# PIC32MZ2025DAR169 device description
Architecture: MIPS; Family: PIC32MZDA; Series: PIC32MZ
Registers are 32-bit, read-write, no defined reset value unless marked. A register's access mark holds for its fields unless they carry their own. Offsets are from the block's base; [hi:lo] are bit positions; {n}, {i} and the like mark numbered series; 'fields as' and 'values as' point back to an identical list.

## GPIO
Instances: GPIO 0x1f860000 in periph_pb4_std
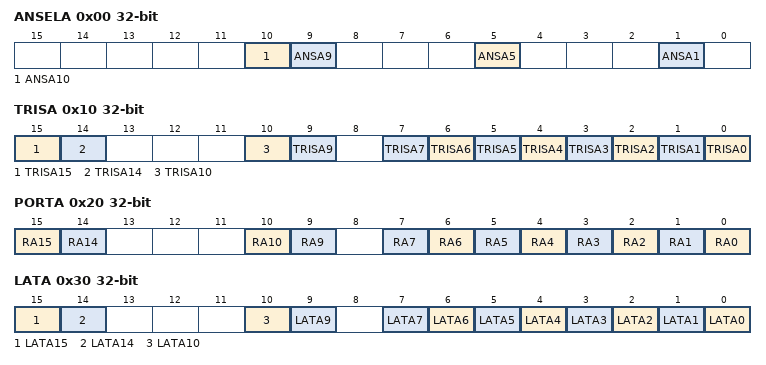
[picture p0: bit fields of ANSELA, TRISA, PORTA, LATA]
0x00 ANSELA
  [10] ANSA10, [9] ANSA9, [5] ANSA5, [1] ANSA1
0x10 TRISA
  [15] TRISA15, [14] TRISA14, [10] TRISA10, [9] TRISA9, [n] TRISA{n} (n=0..7)
0x20 PORTA
  [15] RA15, [14] RA14, [10] RA10, [9] RA9, [n] RA{n} (n=0..7)
0x30 LATA
  [15] LATA15, [14] LATA14, [10] LATA10, [9] LATA9, [n] LATA{n} (n=0..7)
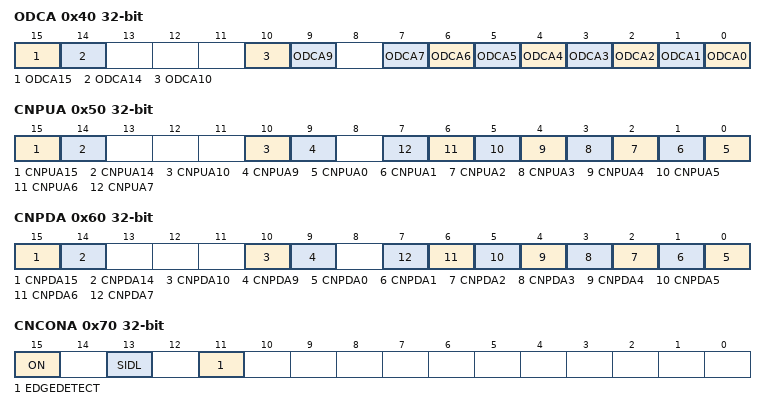
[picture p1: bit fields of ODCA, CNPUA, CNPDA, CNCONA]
0x40 ODCA
  [15] ODCA15, [14] ODCA14, [10] ODCA10, [9] ODCA9, [n] ODCA{n} (n=0..7)
0x50 CNPUA
  [15] CNPUA15, [14] CNPUA14, [10] CNPUA10, [9] CNPUA9, [n] CNPUA{n} (n=0..7)
0x60 CNPDA
  [15] CNPDA15, [14] CNPDA14, [10] CNPDA10, [9] CNPDA9, [n] CNPDA{n} (n=0..7)
0x70 CNCONA — Change Notice control for PORTx Register
  [15] ON — Change Notice Control ON bit
    1=CN is enabled; 0=CN is disabled
  [13] SIDL
  [11] EDGEDETECT — Change Notification Style bit
    1=Edge Style. Detect edge transitions (CNFx used for CN Event).; 0=Mismatch Style. Detect change from last PORTx read (CNSTATx used for CN Event).
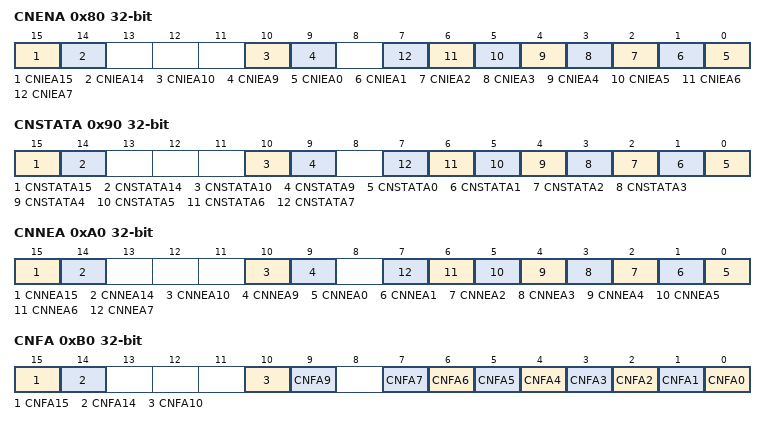
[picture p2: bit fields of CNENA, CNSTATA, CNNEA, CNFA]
0x80 CNENA
  [15] CNIEA15, [14] CNIEA14, [10] CNIEA10, [9] CNIEA9, [n] CNIEA{n} (n=0..7)
0x90 CNSTATA
  [15] CNSTATA15, [14] CNSTATA14, [10] CNSTATA10, [9] CNSTATA9, [n] CNSTATA{n} (n=0..7)
0xA0 CNNEA
  [15] CNNEA15, [14] CNNEA14, [10] CNNEA10, [9] CNNEA9, [n] CNNEA{n} (n=0..7)
0xB0 CNFA
  [15] CNFA15, [14] CNFA14, [10] CNFA10, [9] CNFA9, [n] CNFA{n} (n=0..7)
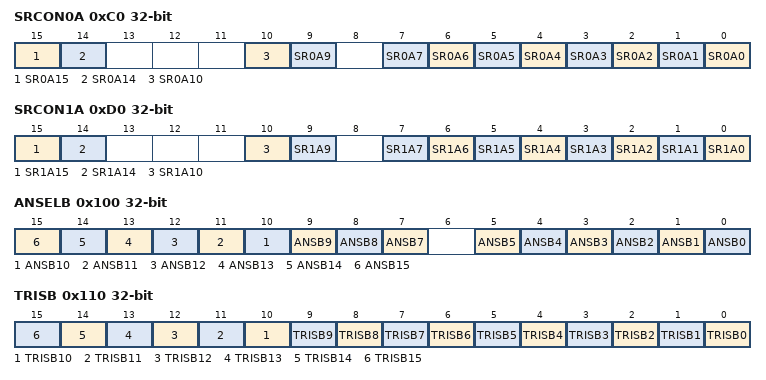
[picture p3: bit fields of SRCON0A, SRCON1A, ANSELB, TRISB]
0xC0 SRCON0A
  [15] SR0A15, [14] SR0A14, [10] SR0A10, [9] SR0A9, [n] SR0A{n} (n=0..7)
0xD0 SRCON1A
  [15] SR1A15, [14] SR1A14, [10] SR1A10, [9] SR1A9, [n] SR1A{n} (n=0..7)
0x100 ANSELB
  [n] ANSB{n} (n=7..15), [n] ANSB{n} (n=0..5)
0x110 TRISB
  [n] TRISB{n} (n=0..15)
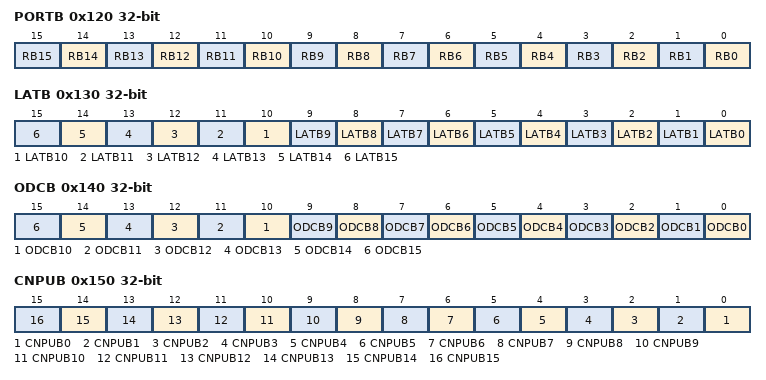
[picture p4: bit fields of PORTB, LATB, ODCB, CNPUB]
0x120 PORTB
  [n] RB{n} (n=0..15)
0x130 LATB
  [n] LATB{n} (n=0..15)
0x140 ODCB
  [n] ODCB{n} (n=0..15)
0x150 CNPUB
  [n] CNPUB{n} (n=0..15)
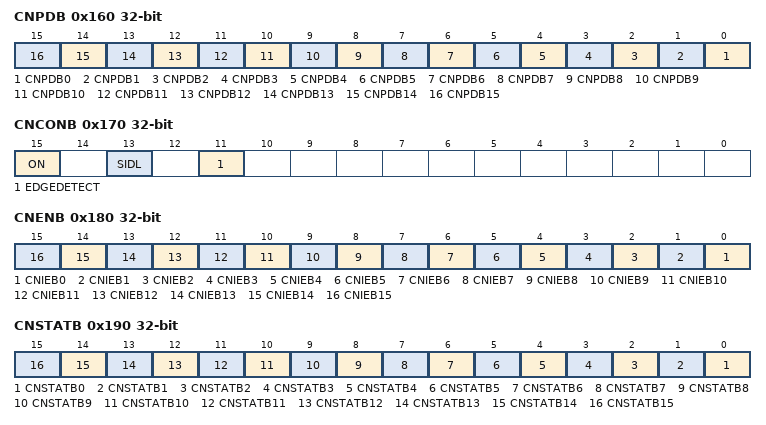
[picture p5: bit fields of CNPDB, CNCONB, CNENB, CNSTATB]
0x160 CNPDB
  [n] CNPDB{n} (n=0..15)
0x170 CNCONB — Change Notice control for PORTx Register
  fields as CNCONA
0x180 CNENB
  [n] CNIEB{n} (n=0..15)
0x190 CNSTATB
  [n] CNSTATB{n} (n=0..15)
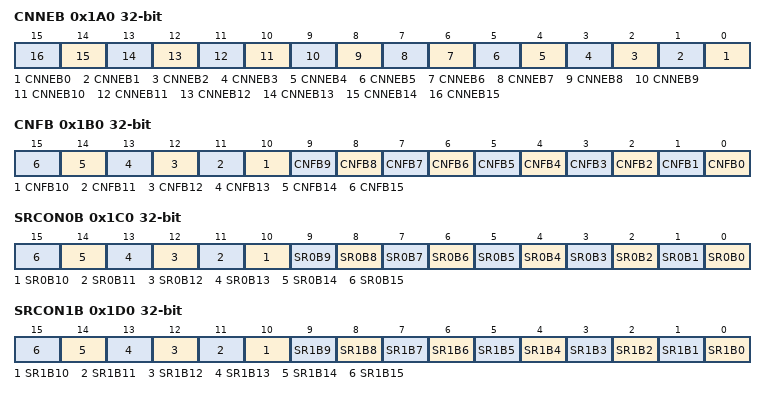
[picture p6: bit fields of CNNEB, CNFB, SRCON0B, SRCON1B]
0x1A0 CNNEB
  [n] CNNEB{n} (n=0..15)
0x1B0 CNFB
  [n] CNFB{n} (n=0..15)
0x1C0 SRCON0B
  [n] SR0B{n} (n=0..15)
0x1D0 SRCON1B
  [n] SR1B{n} (n=0..15)
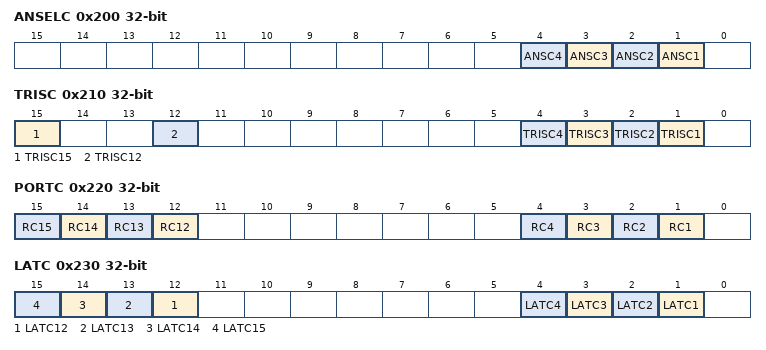
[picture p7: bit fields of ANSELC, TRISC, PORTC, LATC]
0x200 ANSELC
  [n] ANSC{n} (n=1..4)
0x210 TRISC
  [15] TRISC15, [12] TRISC12, [n] TRISC{n} (n=1..4)
0x220 PORTC
  [n] RC{n} (n=12..15), [n] RC{n} (n=1..4)
0x230 LATC
  [n] LATC{n} (n=12..15), [n] LATC{n} (n=1..4)
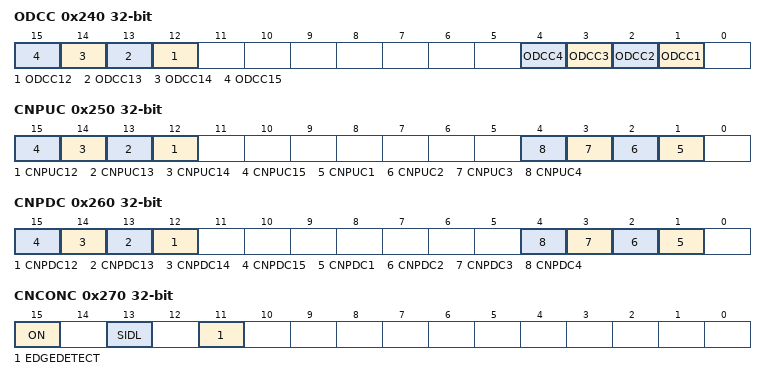
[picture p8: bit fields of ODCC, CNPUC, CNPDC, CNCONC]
0x240 ODCC
  [n] ODCC{n} (n=12..15), [n] ODCC{n} (n=1..4)
0x250 CNPUC
  [n] CNPUC{n} (n=12..15), [n] CNPUC{n} (n=1..4)
0x260 CNPDC
  [n] CNPDC{n} (n=12..15), [n] CNPDC{n} (n=1..4)
0x270 CNCONC — Change Notice control for PORTx Register
  fields as CNCONA
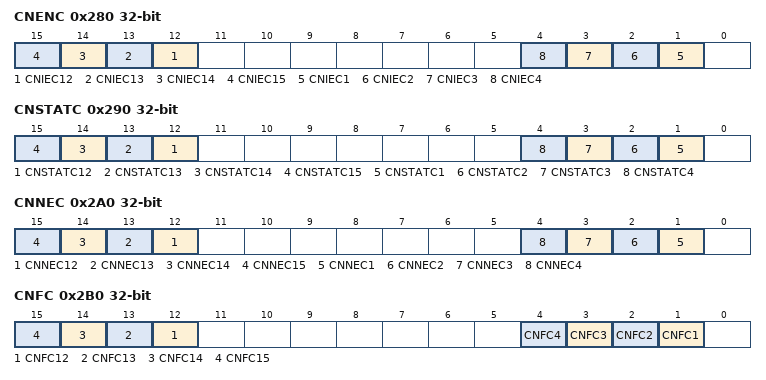
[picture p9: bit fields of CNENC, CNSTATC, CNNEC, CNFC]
0x280 CNENC
  [n] CNIEC{n} (n=12..15), [n] CNIEC{n} (n=1..4)
0x290 CNSTATC
  [n] CNSTATC{n} (n=12..15), [n] CNSTATC{n} (n=1..4)
0x2A0 CNNEC
  [n] CNNEC{n} (n=12..15), [n] CNNEC{n} (n=1..4)
0x2B0 CNFC
  [n] CNFC{n} (n=12..15), [n] CNFC{n} (n=1..4)
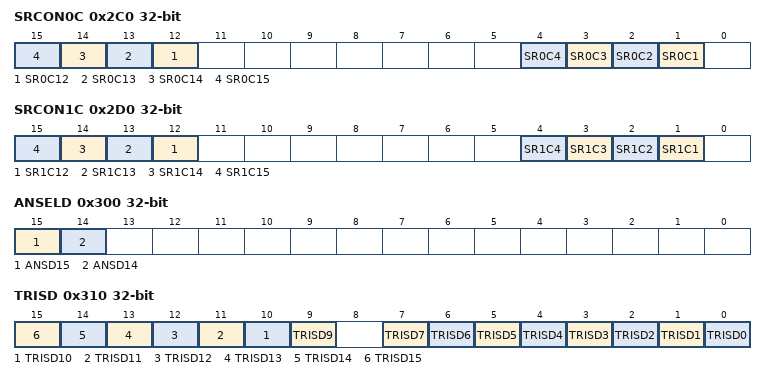
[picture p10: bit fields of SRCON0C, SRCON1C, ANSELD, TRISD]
0x2C0 SRCON0C
  [n] SR0C{n} (n=12..15), [n] SR0C{n} (n=1..4)
0x2D0 SRCON1C
  [n] SR1C{n} (n=12..15), [n] SR1C{n} (n=1..4)
0x300 ANSELD
  [15] ANSD15, [14] ANSD14
0x310 TRISD
  [n] TRISD{n} (n=9..15), [n] TRISD{n} (n=0..7)
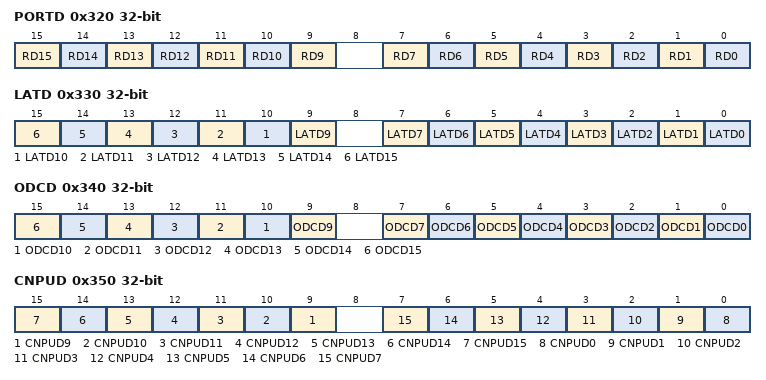
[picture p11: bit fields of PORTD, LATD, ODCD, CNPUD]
0x320 PORTD
  [n] RD{n} (n=9..15), [n] RD{n} (n=0..7)
0x330 LATD
  [n] LATD{n} (n=9..15), [n] LATD{n} (n=0..7)
0x340 ODCD
  [n] ODCD{n} (n=9..15), [n] ODCD{n} (n=0..7)
0x350 CNPUD
  [n] CNPUD{n} (n=9..15), [n] CNPUD{n} (n=0..7)
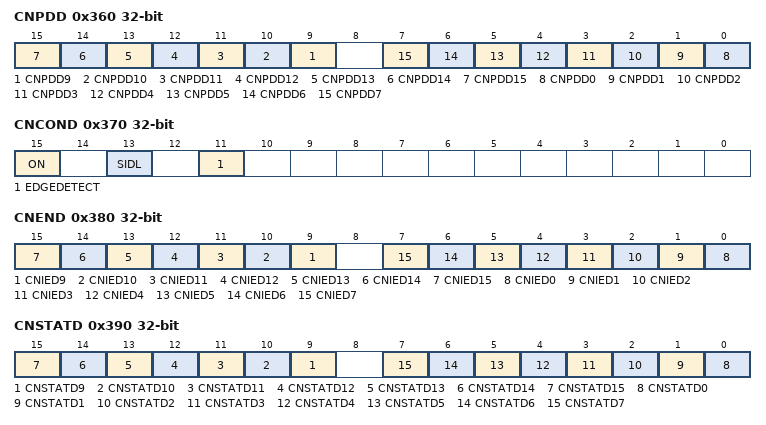
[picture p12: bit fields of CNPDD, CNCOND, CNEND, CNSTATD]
0x360 CNPDD
  [n] CNPDD{n} (n=9..15), [n] CNPDD{n} (n=0..7)
0x370 CNCOND — Change Notice control for PORTx Register
  fields as CNCONA
0x380 CNEND
  [n] CNIED{n} (n=9..15), [n] CNIED{n} (n=0..7)
0x390 CNSTATD
  [n] CNSTATD{n} (n=9..15), [n] CNSTATD{n} (n=0..7)
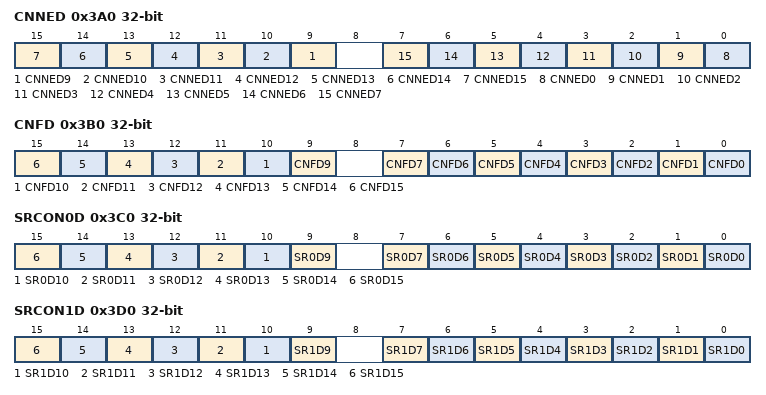
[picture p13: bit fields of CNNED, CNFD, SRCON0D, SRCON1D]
0x3A0 CNNED
  [n] CNNED{n} (n=9..15), [n] CNNED{n} (n=0..7)
0x3B0 CNFD
  [n] CNFD{n} (n=9..15), [n] CNFD{n} (n=0..7)
0x3C0 SRCON0D
  [n] SR0D{n} (n=9..15), [n] SR0D{n} (n=0..7)
0x3D0 SRCON1D
  [n] SR1D{n} (n=9..15), [n] SR1D{n} (n=0..7)
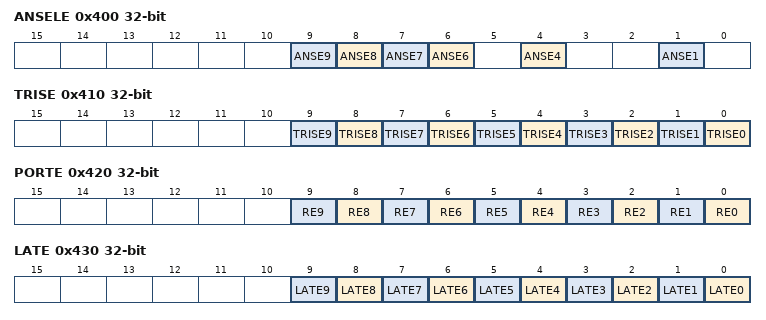
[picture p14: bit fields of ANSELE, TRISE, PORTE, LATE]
0x400 ANSELE
  [n] ANSE{n} (n=6..9), [4] ANSE4, [1] ANSE1
0x410 TRISE
  [n] TRISE{n} (n=0..9)
0x420 PORTE
  [n] RE{n} (n=0..9)
0x430 LATE
  [n] LATE{n} (n=0..9)
0x440 ODCE
  [n] ODCE{n} (n=0..9)
0x450 CNPUE
  [n] CNPUE{n} (n=0..9)
0x460 CNPDE
  [n] CNPDE{n} (n=0..9)
0x470 CNCONE — Change Notice control for PORTx Register
  fields as CNCONA
0x480 CNENE
  [n] CNIEE{n} (n=0..9)
0x490 CNSTATE
  [n] CNSTATE{n} (n=0..9)
0x4A0 CNNEE
  [n] CNNEE{n} (n=0..9)
0x4B0 CNFE
  [n] CNFE{n} (n=0..9)
0x4C0 SRCON0E
  [n] SR0E{n} (n=0..9)
0x4D0 SRCON1E
  [n] SR1E{n} (n=0..9)
0x500 ANSELF
  [13] ANSF13, [12] ANSF12
0x510 TRISF
  [13] TRISF13, [12] TRISF12, [8] TRISF8, [n] TRISF{n} (n=0..5)
0x520 PORTF
  [13] RF13, [12] RF12, [8] RF8, [n] RF{n} (n=0..5)
0x530 LATF
  [13] LATF13, [12] LATF12, [8] LATF8, [n] LATF{n} (n=0..5)
0x540 ODCF
  [13] ODCF13, [12] ODCF12, [8] ODCF8, [n] ODCF{n} (n=0..5)
0x550 CNPUF
  [13] CNPUF13, [12] CNPUF12, [8] CNPUF8, [n] CNPUF{n} (n=0..5)
0x560 CNPDF
  [13] CNPDF13, [12] CNPDF12, [8] CNPDF8, [n] CNPDF{n} (n=0..5)
0x570 CNCONF — Change Notice control for PORTx Register
  fields as CNCONA
0x580 CNENF
  [13] CNIEF13, [12] CNIEF12, [8] CNIEF8, [n] CNIEF{n} (n=0..5)
0x590 CNSTATF
  [13] CNSTATF13, [12] CNSTATF12, [8] CNSTATF8, [n] CNSTATF{n} (n=0..5)
0x5A0 CNNEF
  [13] CNNEF13, [12] CNNEF12, [8] CNNEF8, [n] CNNEF{n} (n=0..5)
0x5B0 CNFF
  [13] CNFF13, [12] CNFF12, [8] CNFF8, [n] CNFF{n} (n=0..5)
0x5C0 SRCON0F
  [13] SR0F13, [12] SR0F12, [8] SR0F8, [n] SR0F{n} (n=0..5)
0x5D0 SRCON1F
  [13] SR1F13, [12] SR1F12, [8] SR1F8, [n] SR1F{n} (n=0..5)
0x600 ANSELG
  [15] ANSG15, [n] ANSG{n} (n=6..9)
0x610 TRISG
  [n] TRISG{n} (n=12..15), [n] TRISG{n} (n=6..9), [1] TRISG1, [0] TRISG0
0x620 PORTG
  [n] RG{n} (n=12..15), [n] RG{n} (n=6..9), [1] RG1, [0] RG0
0x630 LATG
  [n] LATG{n} (n=12..15), [n] LATG{n} (n=6..9), [1] LATG1, [0] LATG0
0x640 ODCG
  [n] ODCG{n} (n=12..15), [n] ODCG{n} (n=6..9), [1] ODCG1, [0] ODCG0
0x650 CNPUG
  [n] CNPUG{n} (n=12..15), [n] CNPUG{n} (n=6..9), [1] CNPUG1, [0] CNPUG0
0x660 CNPDG
  [n] CNPDG{n} (n=12..15), [n] CNPDG{n} (n=6..9), [1] CNPDG1, [0] CNPDG0
0x670 CNCONG — Change Notice control for PORTx Register
  fields as CNCONA
0x680 CNENG
  [n] CNIEG{n} (n=12..15), [n] CNIEG{n} (n=6..9), [1] CNIEG1, [0] CNIEG0
0x690 CNSTATG
  [n] CNSTATG{n} (n=12..15), [n] CNSTATG{n} (n=6..9), [1] CNSTATG1, [0] CNSTATG0
0x6A0 CNNEG
  [n] CNNEG{n} (n=12..15), [n] CNNEG{n} (n=6..9), [1] CNNEG1, [0] CNNEG0
0x6B0 CNFG
  [n] CNFG{n} (n=12..15), [n] CNFG{n} (n=6..9), [1] CNFG1, [0] CNFG0
0x6C0 SRCON0G
  [n] SR0G{n} (n=12..15), [n] SR0G{n} (n=6..9), [1] SR0G1, [0] SR0G0
0x6D0 SRCON1G
  [n] SR1G{n} (n=12..15), [n] SR1G{n} (n=6..9), [1] SR1G1, [0] SR1G0
0x700 ANSELH
  [11] ANSH11, [7] ANSH7, [4] ANSH4, [3] ANSH3
0x710 TRISH
  [n] TRISH{n} (n=0..15)
0x720 PORTH
  [n] RH{n} (n=0..15)
0x730 LATH
  [n] LATH{n} (n=0..15)
0x740 ODCH
  [n] ODCH{n} (n=0..15)
0x750 CNPUH
  [n] CNPUH{n} (n=0..15)
0x760 CNPDH
  [n] CNPDH{n} (n=0..15)
0x770 CNCONH — Change Notice control for PORTx Register
  fields as CNCONA
0x780 CNENH
  [n] CNIEH{n} (n=0..15)
0x790 CNSTATH
  [n] CNSTATH{n} (n=0..15)
0x7A0 CNNEH
  [n] CNNEH{n} (n=0..15)
0x7B0 CNFH
  [n] CNFH{n} (n=0..15)
0x7C0 SRCON0H
  [n] SR0H{n} (n=0..15)
0x7D0 SRCON1H
  [n] SR1H{n} (n=0..15)
0x800 ANSELJ
  [2] ANSJ2
0x810 TRISJ
  [n] TRISJ{n} (n=0..15)
0x820 PORTJ
  [n] RJ{n} (n=0..15)
0x830 LATJ
  [n] LATJ{n} (n=0..15)
0x840 ODCJ
  [n] ODCJ{n} (n=0..15)
0x850 CNPUJ
  [n] CNPUJ{n} (n=0..15)
0x860 CNPDJ
  [n] CNPDJ{n} (n=0..15)
0x870 CNCONJ — Change Notice control for PORTx Register
  fields as CNCONA
0x880 CNENJ
  [n] CNIEJ{n} (n=0..15)
0x890 CNSTATJ
  [n] CNSTATJ{n} (n=0..15)
0x8A0 CNNEJ
  [n] CNNEJ{n} (n=0..15)
0x8B0 CNFJ
  [n] CNFJ{n} (n=0..15)
0x8C0 SRCON0J
  [n] SR0J{n} (n=0..15)
0x8D0 SRCON1J
  [n] SR1J{n} (n=0..15)
0x900 ANSELK
  [2] ANSK2, [1] ANSK1
0x910 TRISK
  [n] TRISK{n} (n=0..7)
0x920 PORTK
  [n] RK{n} (n=0..7)
0x930 LATK
  [n] LATK{n} (n=0..7)
0x940 ODCK
  [n] ODCK{n} (n=0..7)
0x950 CNPUK
  [n] CNPUK{n} (n=0..7)
0x960 CNPDK
  [n] CNPDK{n} (n=0..7)
0x970 CNCONK — Change Notice control for PORTx Register
  fields as CNCONA
0x980 CNENK
  [n] CNIEK{n} (n=0..7)
0x990 CNSTATK
  [n] CNSTATK{n} (n=0..7)
0x9A0 CNNEK
  [n] CNNEK{n} (n=0..7)
0x9B0 CNFK
  [n] CNFK{n} (n=0..7)
0x9C0 SRCON0K
  [n] SR0K{n} (n=0..7)
0x9D0 SRCON1K
  [n] SR1K{n} (n=0..7)

## Notices in the file
Copyright (c) 2017 Microchip Technology Inc.
SPDX-License-Identifier: Apache-2.0
Licensed under the Apache License, Version 2.0 (the "License");
you may not use this file except in compliance with the License.
You may obtain a copy of the License at
http://www.apache.org/licenses/LICENSE-2.0
Unless required by applicable law or agreed to in writing, software
distributed under the License is distributed on an "AS IS" BASIS,
WITHOUT WARRANTIES OR CONDITIONS OF ANY KIND, either express or implied.
See the License for the specific language governing permissions and
limitations under the License.
